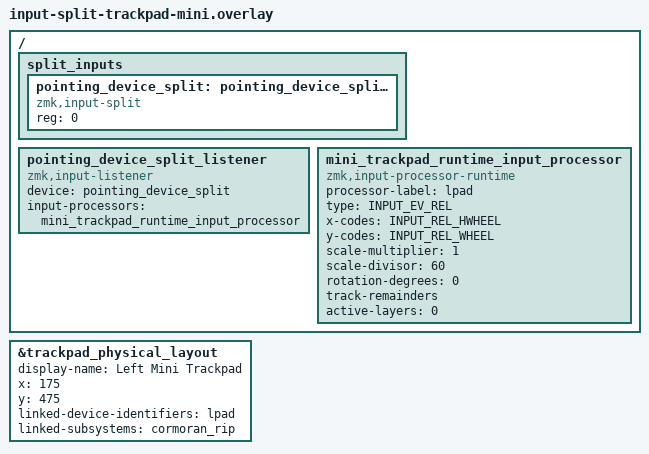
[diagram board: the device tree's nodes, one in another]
/ {
    split_inputs {
        #address-cells = <1>;
        #size-cells = <0>;

        // 左側のinput-splitと同じ番号にし、センサー入力を受け取ります。
        pointing_device_split: pointing_device_split@0 {
            compatible = "zmk,input-split";
            reg = <0>;
        };
    };

    pointing_device_split_listener: pointing_device_split_listener {
        compatible = "zmk,input-listener";
        device = <&pointing_device_split>;
        status = "okay";
        // タップのボタン入力は通過させ、スクロールだけを調整します。
        input-processors = <&mini_trackpad_runtime_input_processor>;
    };

    mini_trackpad_runtime_input_processor: mini_trackpad_runtime_input_processor {
        compatible = "zmk,input-processor-runtime";
        // 設定の保存名も兼ねるため、左トラックボールのlscrollとは別名にします。
        processor-label = "lpad";
        type = <INPUT_EV_REL>;
        x-codes = <INPUT_REL_HWHEEL>;
        y-codes = <INPUT_REL_WHEEL>;

        // 通常スクロール向けの仮の感度です。実機ではStudioから調整できます。
        scale-multiplier = <1>;
        scale-divisor = <60>;
        rotation-degrees = <0>;
        track-remainders;

        // 0は全レイヤーを表します。Mouseレイヤーの自動切替は有効にしません。
        // センサーがWheel入力を作るため、XY→Scrollの変換も不要です。
        active-layers = <0>;
        #input-processor-cells = <0>;
    };
};

// Studioは右Centralの定義を読むため、左側の装置もここで表示します。
// 座標と大きさはM配列の左電池カバー付近を示す代表値で、実寸ではありません。
&trackpad_physical_layout {
    status = "okay";
    display-name = "Left Mini Trackpad";
    x = <175>;
    y = <475>;
    linked-device-identifiers = "lpad";
    linked-subsystems = "cormoran_rip";
};
